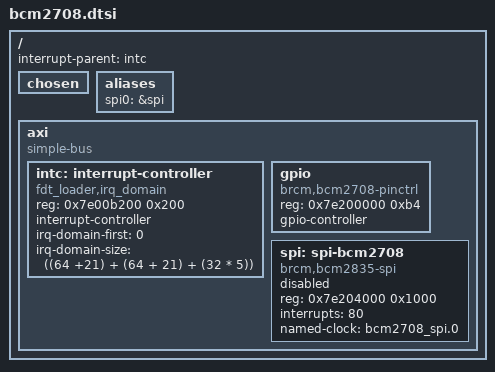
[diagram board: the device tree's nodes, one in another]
/*
 *  Raspberry Pi BCM2708
 */

/ {
	#address-cells = <1>;
	#size-cells = <1>;
	interrupt-parent = <&intc>;

	chosen { };
	aliases {
		spi0 = &spi;
	};

//	leds {
//		compatible = "gpio-leds";
//
//		act {
//			label = "ACT";
//			gpios = <&gpio 16 1>;
//			default-state = "keep";
//			linux,default-trigger = "heartbeat";
//		};
//	};

	axi {
		compatible = "simple-bus";
		#address-cells = <1>;
		#size-cells = <1>;
		ranges = <0x7e000000 0x20000000 0x02000000>;

		intc: interrupt-controller {
			compatible = "fdt_loader,irq_domain";
			reg = <0x7e00b200 0x200>;
			interrupt-controller;
			#interrupt-cells = <1>;
			irq-domain-first = <0>;
			/* NR_IRQS = HARD_IRQS + FIQ_IRQS + GPIO_IRQS */
			irq-domain-size = < ((64 +21) + (64 + 21) + (32 * 5)) >;
		};

		gpio: gpio {
			compatible = "brcm,bcm2708-pinctrl";
			reg = <0x7e200000 0xb4>;
			gpio-controller;
			#gpio-cells = <2>;
		};

		spi: spi-bcm2708 {
			compatible = "brcm,bcm2835-spi", "brcm,bcm2708-spi";
			#address-cells = <1>;
			#size-cells = <0>;
			reg = <0x7e204000 0x1000>;
			interrupts = <80>;
			named-clock = "bcm2708_spi.0";
			status = "disabled";
		};

//		i2c0: i2c@20205000 {
//			compatible = "brcm,bcm2835-i2c", "brcm,bcm2708-i2c";
//			reg = <0x7e205000 0x1000>;
//			interrupts = ??<2 21>;
//			named-clock = "bcm2708_i2c.0";
//			#address-cells = <1>;
//			#size-cells = <0>;
//			status = "disabled";
//		};
//
//		i2c1: i2c@20804000 {
//			compatible = "brcm,bcm2835-i2c", "brcm,bcm2708-i2c";
//			reg = <0x7e804000 0x1000>;
//			interrupts = ??<2 21>;
//			named-clock = "bcm2708_i2c.1";
//			#address-cells = <1>;
//			#size-cells = <0>;
//			status = "disabled";
//		};
	};
};
